# wiz16b8m4ct3_0_WIZ16B8M4CT3 register map
Vendor: Texas Instruments
Registers are 32-bit, read-write, reset 0x0 unless marked. A register's access mark holds for its fields unless they carry their own. Offsets are as the file gives them; [hi:lo] are bit positions; {n}, {i} and the like mark numbered series.

## wiz16b8m4ct3_0_WIZ16B8M4CT3 (part 11 of 12)
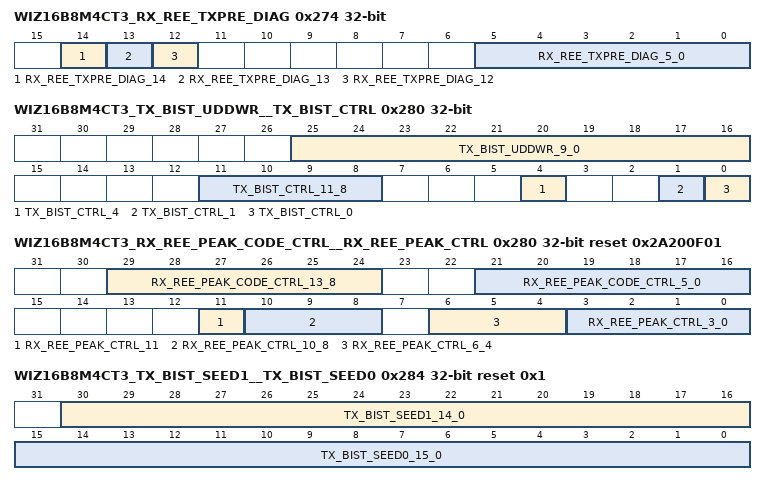
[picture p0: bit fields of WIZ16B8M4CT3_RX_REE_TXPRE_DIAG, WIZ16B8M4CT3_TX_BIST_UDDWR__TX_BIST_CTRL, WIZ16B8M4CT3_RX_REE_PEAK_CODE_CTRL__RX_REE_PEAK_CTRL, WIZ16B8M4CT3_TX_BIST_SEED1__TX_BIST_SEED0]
0x274 WIZ16B8M4CT3_RX_REE_TXPRE_DIAG access per field
  [14] RX_REE_TXPRE_DIAG_14 rw — Voter override neg : Writing a 1'b1 in this register bit will force the tap voter function to activate the voter neg signal for a single clock cycle. Note : This bit must be cleared after each time it is enabled, in order to perform follow on voter override functions with this bit. Note : It is not valid to activate both the voter override neg and voter override pos at the same time.
  [13] RX_REE_TXPRE_DIAG_13 rw — Voter override pos : Writing a 1'b1 in this register bit will force the tap voter function to activate the voter pos signal for a single clock cycle. Note : This bit must be cleared after each time it is enabled, in order to perform follow on voter override functions with this bit. Note : It is not valid to activate both the voter override neg and voter override pos at the same time.
  [12] RX_REE_TXPRE_DIAG_12 rw — Voter override enable : Setting this bit to a 1'b1 will allow only the voter override pos and voter override neg bits in this register to control the voter in the tap. Note : This function is intended to be for diagnostic and verification purposes only. Note : Both the voter override neg and voter override pos bits in this register must be set to 1'b0 when this bit is initially set to 1'b1 when enabling this function.
  [5:0] RX_REE_TXPRE_DIAG_5_0 ro — Current tap integrator accumulator: Current value of the tap integrator accumulator.
0x280 WIZ16B8M4CT3_TX_BIST_UDDWR__TX_BIST_CTRL access per field
  [25:16] TX_BIST_UDDWR_9_0 wo — Transmitter BIST user defined data: Writing a data word to this field will result in that data word being placed in the next available position in the transmitter BIST user defined data FIFO. Note, when in 20 bit mode, all 10 of these bits are used. When in 16 bit mode, only the least significant 8 bits are used. Note: The FIFO in this implementation is 18 words deep. It is up to the user to not write more than 18 words of data into this FIFO. Exceeding this amount of data will generate unpredictable results.
  [11:8] TX_BIST_CTRL_11_8 rw — Transmitter BIST mode: Controls which mode the BIST will operate in. The value of this field must match the corresponding field for the receive BIST controller. The following are the values used for this field, and what BIST mode they correspond to. 4'b0000 : User defined data FIFO 4'b0001 - 4'b0111 : Reserved 4'b1000 : PRBS7 : 7 bit LFSR 4'b1001 : PRBS15 : 15 bit LFSR 4'b1010 : PRBS23 : 23 bit LFSR 4'b1011 : PRBS31 : 31 bit LFSR 4'b1100 - 4'b1111 : Reserved
  [4] TX_BIST_CTRL_4 rw — Transmitter BIST force error: When this bit transitions from 1'b0 to 1'b1, the transmit BIST controller will force an error to be transmitted from the BIST logic, by inverting one of the parallel data bits.
  [1] TX_BIST_CTRL_1 wo — Transmitter BIST user defined data FIFO clear: Writing a 1'b1 to this bit will clear the transmitter BIST user defined data FIFO. Note : This bit is automatically cleared after it is written to. Note : This clear function simply resets the FIFO pointers. It does not clear the contents of the FIFO.
  [0] TX_BIST_CTRL_0 rw — Transmitter BIST enable: This bit enables the transmitter BIST function. Note : The remaining bits in this register must be stable when changing this bit. Therefore, it is best to enable and disable this function using a read / modify / write of this bit.
0x280 WIZ16B8M4CT3_RX_REE_PEAK_CODE_CTRL__RX_REE_PEAK_CTRL reset 0x2A200F01
  [29:24] RX_REE_PEAK_CODE_CTRL_13_8 — Peaking amp code maximum value: This is the maximum value that the peaking amp code will be allowed to increase to. Note: In this application the width of the integrator accumulator is 6, which is one larger that the number of bits required to generate a full 32 bit thermometer code. Therefore, as noted in the description of the REE gain integrator function, the thermometer code is generated using the most significant 5 bits of the integrator accumulator. As a result, the maximum value here needs to be 2X that of the maximum value of the thermometer encoded output.
  [21:16] RX_REE_PEAK_CODE_CTRL_5_0 — Peaking amp initial code: Initial value the peaking amp code is set to when training starts. Note: In this application the width of the integrator accumulator is 6, which is one larger that the number of bits required to generate a full 32 bit thermometer code. Therefore, as noted in the description of the REE gain integrator function, the thermometer code is generated using the most significant 5 bits of the integrator accumulator. As a result, the starting value here needs to be 2X that of the desired starting value of the thermometer encoded output.
  [11] RX_REE_PEAK_CTRL_11 — Peaking amp feedback path enable: Enables the peaking amp feedback path.
  [10:8] RX_REE_PEAK_CTRL_10_8 — Peaking amp feedback scaler value: Specifies the amount to scale the peaking amp feedback by. The following are the valid settings for this signal: 3'b110 : /4 3'b111 : /2 3'b000 : x1 3'b001 : x2 3'b010 : x4
  [6:4] RX_REE_PEAK_CTRL_6_4 — Peaking amp integrator accumulator scaler value: Specifies the amount to scale the input to the peaking amp integrator accumulator by. The following are the valid settings for this field: 3'b000: x1 3'b001: x2 3'b010: x4 3'b011: x8 3'b100: x16 3'b101 - 3'b111: Reserved
  [3:0] RX_REE_PEAK_CTRL_3_0 — Peaking amp sigma delta accumulator scaler value: Specifies the amount to scale the input to the peaking amp sigma delta accumulator by. The following are the valid settings for this field: 4'b0000: x1 4'b0001: x2 4'b0010: x4 4'b0011: x8 4'b0100: x16 4'b0101: x 32 4'b0110: x 64 4'b0111: x128 4'b1000: x256 4'b1001: x512 4'b1010: x1024 4'b1011: x2048 4'b1100: x 4096 4'b1101 x 8192 4'b1110 x 16384 4'b1111 x 32768
0x284 WIZ16B8M4CT3_TX_BIST_SEED1__TX_BIST_SEED0 reset 0x1
  [30:16] TX_BIST_SEED1_14_0 — Transmitter BIST PRBS seed (30:16): When the BIST is in PRBS mode, this field provides a seed for the PRBS, such that different lanes can have different BIST patterns. Note: This field contains the most significant 15 bits of the full 31 bit seed value. Note: When combined, this register and the Transmit BIST PRBS seed 0 register on page 223 must never be all 0s.
  [15:0] TX_BIST_SEED0_15_0 — Transmitter BIST PRBS seed (15:0): When the BIST is in PRBS mode, this field provides a seed for the PRBS, such that different lanes can have different BIST patterns. Note: This field contains the least significant 16 bits of the full 31 bit seed value. Note: When combined, this register and the Transmit BIST PRBS seed 1 register on page 224 must never be all 0s.
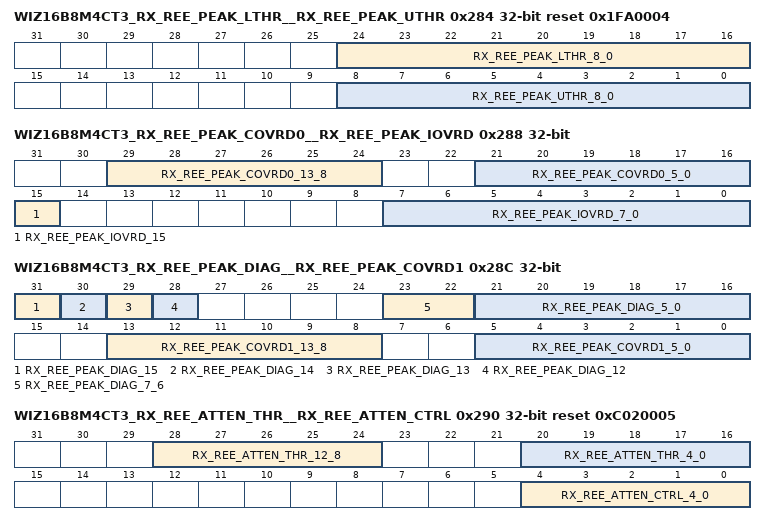
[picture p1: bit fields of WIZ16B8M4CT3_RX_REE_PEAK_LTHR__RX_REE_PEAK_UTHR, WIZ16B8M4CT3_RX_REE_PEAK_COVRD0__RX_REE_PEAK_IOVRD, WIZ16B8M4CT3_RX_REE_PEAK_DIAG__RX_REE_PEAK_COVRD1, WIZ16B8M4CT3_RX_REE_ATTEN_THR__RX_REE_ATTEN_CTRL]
0x284 WIZ16B8M4CT3_RX_REE_PEAK_LTHR__RX_REE_PEAK_UTHR reset 0x1FA0004
  [24:16] RX_REE_PEAK_LTHR_8_0 — Peaking amp algorithm lower threshold: This is the lower threshold value used in the peaking amp algorithm.
  [8:0] RX_REE_PEAK_UTHR_8_0 — Peaking amp algorithm upper threshold: This is the upper threshold value used in the peaking amp algorithm.
0x288 WIZ16B8M4CT3_RX_REE_PEAK_COVRD0__RX_REE_PEAK_IOVRD
  [29:24] RX_REE_PEAK_COVRD0_13_8 — Peaking amp code override value mode 1: Value that will override the peaking amp code when in standard mode 1 when the peaking amp code override enable bit in the REE peaking amp diagnostics register (!) on page 276 is active. The value of this override field will ultimately drive the thermometer encoded value on the rxda_dfe_peaking_amp_gain signal driven to the analog.
  [21:16] RX_REE_PEAK_COVRD0_5_0 — Peaking amp code override value mode 0: Value that will override the peaking amp code when in standard mode 0 when the peaking amp code override enable bit in the REE peaking amp diagnostics register (!) on page 276 is active. The value of this override field will ultimately drive the thermometer encoded value on the rxda_dfe_peaking_amp_gain signal driven to the analog.
  [15] RX_REE_PEAK_IOVRD_15 — Peaking amp tap accumulator input override enable: Setting this bit to a 1'b1 will allow the tap accumulator input in the peaking amp gain algorithm to be overridden by the peaking amp tap accumulator input override field in this register.
  [7:0] RX_REE_PEAK_IOVRD_7_0 — Peaking amp tap accumulator input override : Value that will override the tap accumulator input in the peaking amp gain algorithm, when the Peaking amp tap accumulator input override enable bit is active.
0x28C WIZ16B8M4CT3_RX_REE_PEAK_DIAG__RX_REE_PEAK_COVRD1 access per field
  [31] RX_REE_PEAK_DIAG_15 rw — Peaking amp code override enable: Setting this bit to a 1'b1 will allow the peaking amp code to be overridden by the peaking amp code override value fields in the REE peaking amp code override 0 register (!) on page 274 and REE peaking amp code override 1 register (!) on page 275.
  [30] RX_REE_PEAK_DIAG_14 rw — Voter override neg : Writing a 1'b1 in this register bit will force the peaking amp voter function to activate the voter neg signal for a single clock cycle. Note : This bit must be cleared after each time it is enabled, in order to perform follow on voter override functions with this bit. Note : It is not valid to activate both the voter override neg and voter override pos at the same time.
  [29] RX_REE_PEAK_DIAG_13 rw — Voter override pos : Writing a 1'b1 in this register bit will force the peaking amp voter function to activate the voter pos signal for a single clock cycle. Note : This bit must be cleared after each time it is enabled, in order to perform follow on voter override functions with this bit. Note : It is not valid to activate both the voter override neg and voter override pos at the same time.
  [28] RX_REE_PEAK_DIAG_12 rw — Voter override enable : Setting this bit to a 1'b1 will allow only the voter override pos and voter override neg bits in this register to control the voter in the peaking amp. Note : This function is intended to be for diagnostic and verification purposes only. Note : Both the voter override neg and voter override pos bits in this register must be set to 1'b0 when this bit is initially set to 1'b1 when enabling this function.
  [23:22] RX_REE_PEAK_DIAG_7_6 ro — Reserved Note : n = CODE_WIDTH.
  [21:16] RX_REE_PEAK_DIAG_5_0 ro — Current peaking amp integrator accumulator: Current value of the tap integrator accumulator, without the unused sign bit. Note: The reset value for this field is with the transceiver data path power island switched off. In cases where this power island is switched on, the reset value be 6'b100000
  [13:8] RX_REE_PEAK_COVRD1_13_8 rw — Peaking amp code override value mode 3: Value that will override the peaking amp code when in standard mode 3 when the peaking amp code override enable bit in the REE peaking amp diagnostics register (!) on page 276 is active. The value of this override field will ultimately drive the thermometer encoded value on the rxda_dfe_peaking_amp_gain signal driven to the analog.
  [5:0] RX_REE_PEAK_COVRD1_5_0 rw — Peaking amp code override value mode 2: Value that will override the peaking amp code when in standard mode 2 when the peaking amp code override enable bit in the REE peaking amp diagnostics register (!) on page 276 is active. The value of this override field will ultimately drive the thermometer encoded value on the rxda_dfe_peaking_amp_gain signal driven to the analog.
0x290 WIZ16B8M4CT3_RX_REE_ATTEN_THR__RX_REE_ATTEN_CTRL reset 0xC020005
  [28:24] RX_REE_ATTEN_THR_12_8 — Attenuation high threshold value: High threshold value to compare against the VGA gain accumulator value. Note: The value on this field is not a twos complement value (There is no sign bit and it is always a positive number).
  [20:16] RX_REE_ATTEN_THR_4_0 — Attenuation low threshold value: Low threshold value to compare against the VGA gain accumulator value. Note: The value on this field is not a twos complement value (There is no sign bit and it is always a positive number).
  [4:0] RX_REE_ATTEN_CTRL_4_0 — Receiver DFE attenuation maximum value: The maximum value the rxda_dfe_attenuation_bin will increase to. Note: The value on this field is not a twos complement value (There is no sign bit and it is always a positive number).
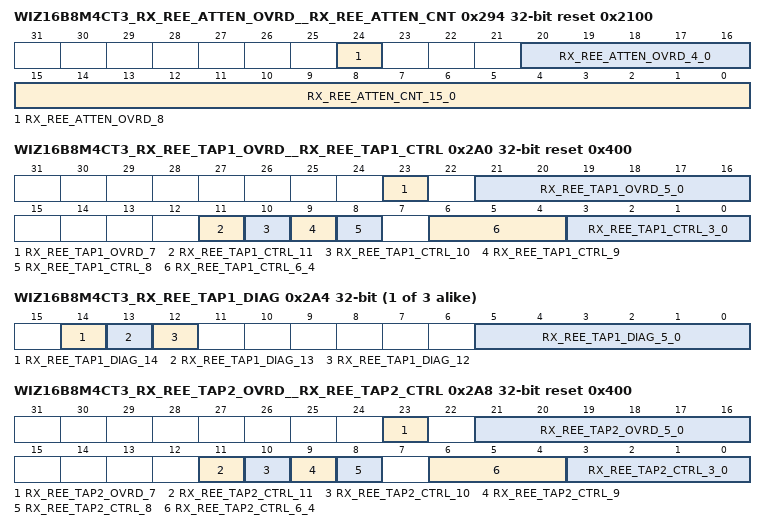
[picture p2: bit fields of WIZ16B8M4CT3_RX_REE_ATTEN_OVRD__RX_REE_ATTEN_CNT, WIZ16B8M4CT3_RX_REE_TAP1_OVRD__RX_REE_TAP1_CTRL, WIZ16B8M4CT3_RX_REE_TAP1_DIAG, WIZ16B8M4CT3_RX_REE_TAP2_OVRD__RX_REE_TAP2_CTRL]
0x294 WIZ16B8M4CT3_RX_REE_ATTEN_OVRD__RX_REE_ATTEN_CNT reset 0x2100
  [24] RX_REE_ATTEN_OVRD_8 — Attenuation override enable: Setting this bit to a 1'b1 will allow the rxda_dfe_attenuation_bin signal to be overridden by the attenuation override value signal in this register.
  [20:16] RX_REE_ATTEN_OVRD_4_0 — Attenuation override value: When enabled by the attenuation override enable bit in this register, this value will override the current attenuation value on the rxda_dfe_attenuation_bin output pin, and also force a corresponding change on the rxda_dfe_attenuation_therm pin. The following specifies the values that can be written to this register. 6'b000000: Min 6'b000001 6'b000011 6'b000111 6'b001111 6'b011111 6'b111111: Max
  [15:0] RX_REE_ATTEN_CNT_15_0 — Attenuation counter max: Value used to specify the maximum number of consecutive words above or below the specified thresholds which will result in triggering an increase or decrease in the rxda_dfe_attenuation_bin signal.
0x298 WIZ16B8M4CT3_RX_REE_ATTEN_DIAG ro
  [4:0] RX_REE_ATTEN_DIAG_4_0 — Current attenuation value: Current value of the attenuation.
0x2A0 WIZ16B8M4CT3_RX_REE_TAP1_OVRD__RX_REE_TAP1_CTRL reset 0x400
  [23] RX_REE_TAP1_OVRD_7 — Tap override enable: Setting this bit to a 1'b1 will enable the tap override field in this register to override the tap integrator accumulator functions.
  [21:16] RX_REE_TAP1_OVRD_5_0 — Tap override value: When the tap override enable bit in this register is active, the value in this field will override the integrator accumulator value, as well as the input to the binary to thermometer encoder.
  [11] RX_REE_TAP1_CTRL_11 — Tap coefficient combinational logic zero crossing enable: 1'b0: Zero crossing combinational logic input not enabled. 1'b1: Zero crossing combinational logic input enabled.
  [10] RX_REE_TAP1_CTRL_10 — Tap coefficient combinational logic non zero crossing enable: 1'b0: non zero crossing combinational logic input not enabled. 1'b1: non zero crossing combinational logic input enabled.
  [9] RX_REE_TAP1_CTRL_9 — Tap coefficient combinational logic bit 0 only enable: 1'b0: All enabled combinational logic input modules will be used. 1'b1: Only the enabled combinational logic input modules associated with bit 0 will be used.
  [8] RX_REE_TAP1_CTRL_8 — Receiver DFE tap coefficient disable: This bit disables the rxda_dfe_tap_coef output signal. 1'b0 : rxda_dfe_tap_coef output enabled. 1'b1 : rxda_dfe_tap_coef output disabled (all 0s).
  [6:4] RX_REE_TAP1_CTRL_6_4 — Tap integrator accumulator scaler value: Specifies the amount to scale the input to the tap integrator accumulator by. The following are the valid settings for this field: 3'b000: x1 3'b001 - 3'b111: Reserved
  [3:0] RX_REE_TAP1_CTRL_3_0 — Tap sigma delta accumulator scaler value: Specifies the amount to scale the input to the tap sigma delta accumulator by. The following are the valid settings for this field: 4'b0000: x1 4'b0001: x2 4'b0010: x4 4'b0011: x8 4'b0100: x16 4'b0101: x 32 4'b0110: x 64 4'b0111: x128 4'b1000: x256 4'b1001: x512 4'b1010: x1024 4'b1011: x2048 4'b1100: x 4096 4'b1101 x 8192 4'b1110 x 16384 4'b1111 x 32768
{0x29C+8i} WIZ16B8M4CT3_RX_REE_TAP{i}_DIAG access per field (i=1..3)
  [14] RX_REE_TAP{i}_DIAG_14 rw — Voter override neg : Writing a 1'b1 in this register bit will force the tap voter function to activate the voter neg signal for a single clock cycle. Note : This bit must be cleared after each time it is enabled, in order to perform follow on voter override functions with this bit. Note : It is not valid to activate both the voter override neg and voter override pos at the same time.
  [13] RX_REE_TAP{i}_DIAG_13 rw — Voter override pos : Writing a 1'b1 in this register bit will force the tap voter function to activate the voter pos signal for a single clock cycle. Note : This bit must be cleared after each time it is enabled, in order to perform follow on voter override functions with this bit. Note : It is not valid to activate both the voter override neg and voter override pos at the same time.
  [12] RX_REE_TAP{i}_DIAG_12 rw — Voter override enable : Setting this bit to a 1'b1 will allow only the voter override pos and voter override neg bits in this register to control the voter in the tap. Note : This function is intended to be for diagnostic and verification purposes only. Note : Both the voter override neg and voter override pos bits in this register must be set to 1'b0 when this bit is initially set to 1'b1 when enabling this function.
  [5:0] RX_REE_TAP{i}_DIAG_5_0 ro — Current tap integrator accumulator: Current value of the tap integrator accumulator.
0x2A8 WIZ16B8M4CT3_RX_REE_TAP2_OVRD__RX_REE_TAP2_CTRL reset 0x400
  [23] RX_REE_TAP2_OVRD_7 — Tap override enable: Setting this bit to a 1'b1 will enable the tap override field in this register to override the tap integrator accumulator functions.
  [21:16] RX_REE_TAP2_OVRD_5_0 — Tap override value: When the tap override enable bit in this register is active, the value in this field will override the integrator accumulator value, as well as the input to the binary to thermometer encoder.
  [11] RX_REE_TAP2_CTRL_11 — Tap coefficient combinational logic zero crossing enable: 1'b0: Zero crossing combinational logic input not enabled. 1'b1: Zero crossing combinational logic input enabled. (This mode is currently not supported)
  [10] RX_REE_TAP2_CTRL_10 — Tap coefficient combinational logic non zero crossing enable: 1'b0: non zero crossing combinational logic input not enabled. 1'b1: non zero crossing combinational logic input enabled.
  [9] RX_REE_TAP2_CTRL_9 — Tap coefficient combinational logic bit 0 only enable: 1'b0: All enabled combinational logic input modules will be used. 1'b1: Only the enabled combinational logic input modules associated with bit 0 will be used.
  [8] RX_REE_TAP2_CTRL_8 — Receiver DFE tap coefficient disable: This bit disables the rxda_dfe_tap_coef output signal. 1'b0 : rxda_dfe_tap_coef output enabled. 1'b1 : rxda_dfe_tap_coef output disabled (all 0s).
  [6:4] RX_REE_TAP2_CTRL_6_4 — Tap integrator accumulator scaler value: Specifies the amount to scale the input to the tap integrator accumulator by. The following are the valid settings for this field: 3'b000: x1 3'b001 - 3'b111: Reserved
  [3:0] RX_REE_TAP2_CTRL_3_0 — Tap sigma delta accumulator scaler value: Specifies the amount to scale the input to the tap sigma delta accumulator by. The following are the valid settings for this field: 4'b0000: x1 4'b0001: x2 4'b0010: x4 4'b0011: x8 4'b0100: x16 4'b0101: x 32 4'b0110: x 64 4'b0111: x128 4'b1000: x256 4'b1001: x512 4'b1010: x1024 4'b1011: x2048 4'b1100: x 4096 4'b1101 x 8192 4'b1110 x 16384 4'b1111 x 32768
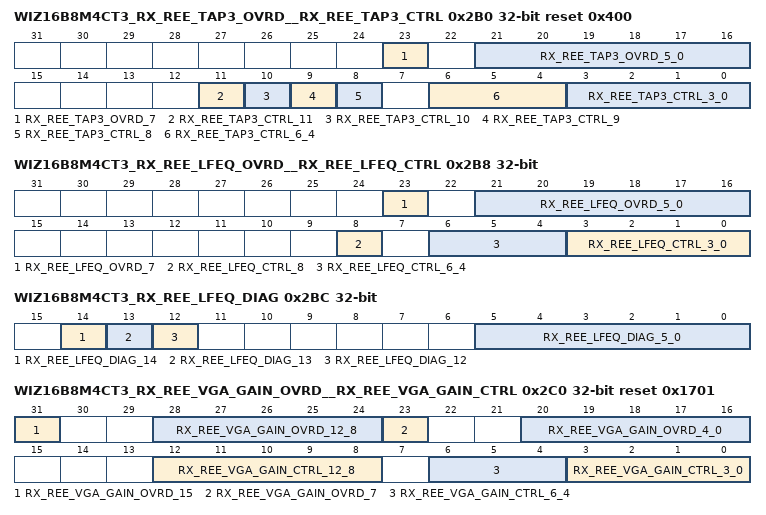
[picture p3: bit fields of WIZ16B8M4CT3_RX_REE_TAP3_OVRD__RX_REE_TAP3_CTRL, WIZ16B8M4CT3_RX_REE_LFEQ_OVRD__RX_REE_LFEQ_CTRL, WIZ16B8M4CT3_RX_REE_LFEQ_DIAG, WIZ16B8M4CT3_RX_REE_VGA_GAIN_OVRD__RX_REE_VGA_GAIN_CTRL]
0x2B0 WIZ16B8M4CT3_RX_REE_TAP3_OVRD__RX_REE_TAP3_CTRL reset 0x400
  [23] RX_REE_TAP3_OVRD_7 — Tap override enable: Setting this bit to a 1'b1 will enable the tap override field in this register to override the tap integrator accumulator functions.
  [21:16] RX_REE_TAP3_OVRD_5_0 — Tap override value: When the tap override enable bit in this register is active, the value in this field will override the integrator accumulator value, as well as the input to the binary to thermometer encoder.
  [11] RX_REE_TAP3_CTRL_11 — Tap coefficient combinational logic zero crossing enable: 1'b0: Zero crossing combinational logic input not enabled. 1'b1: Zero crossing combinational logic input enabled. (This mode is currently not supported)
  [10] RX_REE_TAP3_CTRL_10 — Tap coefficient combinational logic non zero crossing enable: 1'b0: non zero crossing combinational logic input not enabled. 1'b1: non zero crossing combinational logic input enabled.
  [9] RX_REE_TAP3_CTRL_9 — Tap coefficient combinational logic bit 0 only enable: 1'b0: All enabled combinational logic input modules will be used. 1'b1: Only the enabled combinational logic input modules associated with bit 0 will be used.
  [8] RX_REE_TAP3_CTRL_8 — Receiver DFE tap coefficient disable: This bit disables the rxda_dfe_tap_coef output signal. 1'b0 : rxda_dfe_tap_coef output enabled. 1'b1 : rxda_dfe_tap_coef output disabled (all 0s).
  [6:4] RX_REE_TAP3_CTRL_6_4 — Tap integrator accumulator scaler value: Specifies the amount to scale the input to the tap integrator accumulator by. The following are the valid settings for this field: 3'b000: x1 3'b001 - 3'b111: Reserved
  [3:0] RX_REE_TAP3_CTRL_3_0 — Tap sigma delta accumulator scaler value: Specifies the amount to scale the input to the tap sigma delta accumulator by. The following are the valid settings for this field: 4'b0000: x1 4'b0001: x2 4'b0010: x4 4'b0011: x8 4'b0100: x16 4'b0101: x 32 4'b0110: x 64 4'b0111: x128 4'b1000: x256 4'b1001: x512 4'b1010: x1024 4'b1011: x2048 4'b1100: x 4096 4'b1101 x 8192 4'b1110 x 16384 4'b1111 x 32768
0x2B8 WIZ16B8M4CT3_RX_REE_LFEQ_OVRD__RX_REE_LFEQ_CTRL
  [23] RX_REE_LFEQ_OVRD_7 — Override enable: Setting this bit to a 1'b1 will enable the override field in this register to override the integrator accumulator functions.
  [21:16] RX_REE_LFEQ_OVRD_5_0 — Override value: When the override enable bit in this register is active, the value in this field will override the integrator accumulator value, as well as the input to the binary to thermometer encoder.
  [8] RX_REE_LFEQ_CTRL_8 — Receiver DFE coefficient disable: This bit disables the rxda_dfe_coef output signal. 1'b0 : rxda_dfe_coef output enabled. 1'b1 : rxda_dfe_coef output disabled (all 0s).
  [6:4] RX_REE_LFEQ_CTRL_6_4 — Integrator accumulator scaler value: Specifies the amount to scale the input to the integrator accumulator by. The following are the valid settings for this field: 3'b000: x1 3'b001: x2 3'b010: x4 3'b011: x8 3'b100: x16 3'b101 - 3'b111: Reserved
  [3:0] RX_REE_LFEQ_CTRL_3_0 — Sigma delta accumulator scaler value: Specifies the amount to scale the input to the sigma delta accumulator by. The following are the valid settings for this field: 4'b0000: x1 4'b0001: x2 4'b0010: x4 4'b0011: x8 4'b0100: x16 4'b0101: x 32 4'b0110: x 64 4'b0111: x128 4'b1000: x256 4'b1001: x512 4'b1010: x1024 4'b1011: x2048 4'b1100: x 4096 4'b1101 x 8192 4'b1110 x 16384 4'b1111 x 32768
0x2BC WIZ16B8M4CT3_RX_REE_LFEQ_DIAG access per field
  [14] RX_REE_LFEQ_DIAG_14 rw — Voter override neg : Writing a 1'b1 in this register bit will force the voter function to activate the voter neg signal for a single clock cycle. Note : This bit must be cleared after each time it is enabled, in order to perform follow on voter override functions with this bit. Note : It is not valid to activate both the voter override neg and voter override pos at the same time.
  [13] RX_REE_LFEQ_DIAG_13 rw — Voter override pos : Writing a 1'b1 in this register bit will force the voter function to activate the voter pos signal for a single cycle. Note : This bit must be cleared after each time it is enabled, in order to perform follow on voter override functions with this bit. Note : It is not valid to activate both the voter override neg and voter override pos at the same time.
  [12] RX_REE_LFEQ_DIAG_12 rw — Voter override enable : Setting this bit to a 1'b1 will allow only the voter override pos and voter override neg bits in this register to control the voter. Note : This function is intended to be for diagnostic and verification purposes only. Note : Both the voter override neg and voter override pos bits in this register must be set to 1'b0 when this bit is initially set to 1'b1 when enabling this function.
  [5:0] RX_REE_LFEQ_DIAG_5_0 ro — Current integrator accumulator: Current value of the integrator accumulator.
0x2C0 WIZ16B8M4CT3_RX_REE_VGA_GAIN_OVRD__RX_REE_VGA_GAIN_CTRL reset 0x1701
  [31] RX_REE_VGA_GAIN_OVRD_15 — VGA gain target adjust override enable: Setting this bit to a 1'b1 will enable the VGA gain target adjust override field in this register to override the VGA gain target adjust accumulator functions.
  [28:24] RX_REE_VGA_GAIN_OVRD_12_8 — VGA gain target adjust override value: When the VGA gain target adjust override enable bit in this register is active, the value in this field will override the accumulator value used to drive the vga_gain_tgt_adj signal.
  [23] RX_REE_VGA_GAIN_OVRD_7 — VGA gain override enable: Setting this bit to a 1'b1 will enable the VGA gain override field in this register to override the VGA gain integrator accumulator functions.
  [20:16] RX_REE_VGA_GAIN_OVRD_4_0 — VGA gain override value: When the VGA gain override enable bit in this register is active, the value in this field will override the integrator accumulator value, as well as the input to the binary to thermometer encoder.
  [12:8] RX_REE_VGA_GAIN_CTRL_12_8 — VGA gain max: Specifies the maximum value of the VGA gain integrator accumulator, and therefore also the maximum number of bits in the rxda_dfe_vga_gain thermometer code that will be set.
  [6:4] RX_REE_VGA_GAIN_CTRL_6_4 — VGA gain integrator accumulator scaler value: Specifies the amount to scale the input to the VGA gain integrator accumulator by. The following are the valid settings for this field: 3'b000: x1 3'b001: x2 3'b010: x4 3'b011: x8 3'b100: x16 3'b101 - 3'b111: Reserved
  [3:0] RX_REE_VGA_GAIN_CTRL_3_0 — VGA gain sigma delta accumulator scaler value: Specifies the amount to scale the input to the VGA gain sigma delta accumulator by. The following are the valid settings for this field: 4'b0000: x1 4'b0001: x2 4'b0010: x4 4'b0011: x8 4'b0100: x16 4'b0101: x 32 4'b0110: x 64 4'b0111: x128 4'b1000: x256 4'b1001: x512 4'b1010: x1024 4'b1011: x2048 4'b1100: x 4096 4'b1101 x 8192 4'b1110 x 16384 4'b1111 x 32768
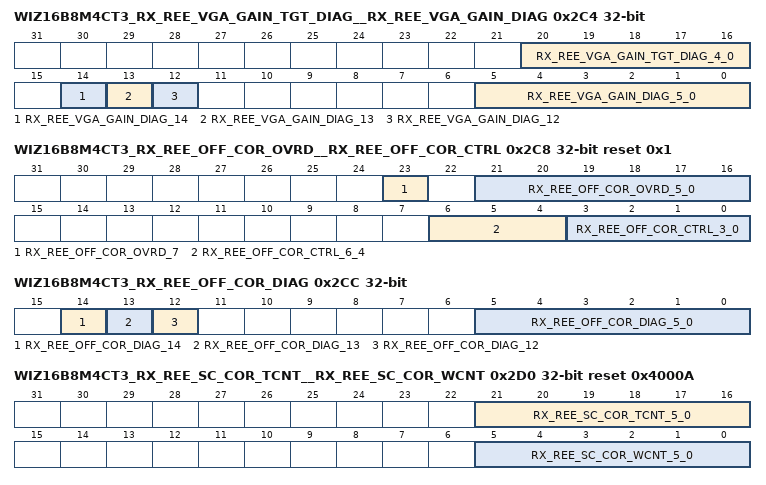
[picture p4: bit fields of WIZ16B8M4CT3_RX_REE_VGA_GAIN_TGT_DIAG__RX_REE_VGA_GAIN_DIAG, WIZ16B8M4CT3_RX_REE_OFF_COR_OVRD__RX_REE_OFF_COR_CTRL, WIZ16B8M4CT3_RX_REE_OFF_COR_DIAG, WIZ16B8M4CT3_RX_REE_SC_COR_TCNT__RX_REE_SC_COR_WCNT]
0x2C4 WIZ16B8M4CT3_RX_REE_VGA_GAIN_TGT_DIAG__RX_REE_VGA_GAIN_DIAG access per field
  [20:16] RX_REE_VGA_GAIN_TGT_DIAG_4_0 ro — Current VGA gain integrator accumulator: Current value of the VGA gain integrator accumulator.
  [14] RX_REE_VGA_GAIN_DIAG_14 rw — Voter override neg : Writing a 1'b1 in this register bit will force the VGA gain voter function to activate the voter neg signal for a single clock cycle. Note : This bit must be cleared after each time it is enabled, in order to perform follow on voter override functions with this bit. Note : It is not valid to activate both the voter override neg and voter override pos at the same time.
  [13] RX_REE_VGA_GAIN_DIAG_13 rw — Voter override pos : Writing a 1'b1 in this register bit will force the VGA gain voter function to activate the voter pos signal for a single clock cycle. Note : This bit must be cleared after each time it is enabled, in order to perform follow on voter override functions with this bit. Note : It is not valid to activate both the voter override neg and voter override pos at the same time.
  [12] RX_REE_VGA_GAIN_DIAG_12 rw — Voter override enable : Setting this bit to a 1'b1 will allow only the voter override pos and voter override neg bits in this register to control the voter in the VGA gain. Note : This function is intended to be for diagnostic and verification purposes only. Note : Both the voter override neg and voter override pos bits in this register must be set to 1'b0 when this bit is initially set to 1'b1 when enabling this function.
  [5:0] RX_REE_VGA_GAIN_DIAG_5_0 ro — Current VGA gain integrator accumulator: Current value of the VGA gain integrator accumulator. Note: The reset value for this field is with the transceiver data path power island switched off. In cases where this power island is switched on, the reset value be 6'b001010
0x2C8 WIZ16B8M4CT3_RX_REE_OFF_COR_OVRD__RX_REE_OFF_COR_CTRL reset 0x1
  [23] RX_REE_OFF_COR_OVRD_7 — Offset correction override enable: Setting this bit to a 1'b1 will enable the offset correction override field in this register to override the offset correction integrator accumulator functions.
  [21:16] RX_REE_OFF_COR_OVRD_5_0 — Offset correction override value: When the offset correction override enable bit in this register is active, the value in this field will override the integrator accumulator value, as well as the input to the binary to thermometer encoder.
  [6:4] RX_REE_OFF_COR_CTRL_6_4 — Offset correction integrator accumulator scaler value: Specifies the amount to scale the input to the offset correction integrator accumulator by. The following are the valid settings for this field: 3'b000: x1 3'b001: x2 3'b010: x4 3'b011: x8 3'b100: x16 3'b101 - 3'b111: Reserved
  [3:0] RX_REE_OFF_COR_CTRL_3_0 — Offset correction sigma delta accumulator scaler value: Specifies the amount to scale the input to the offset correction sigma delta accumulator by. The following are the valid settings for this field: 4'b0000: x1 4'b0001: x2 4'b0010: x4 4'b0011: x8 4'b0100: x16 4'b0101: x 32 4'b0110: x 64 4'b0111: x128 4'b1000: x256 4'b1001: x512 4'b1010: x1024 4'b1011: x2048 4'b1100: x 4096 4'b1101 x 8192 4'b1110 x 16384 4'b1111 x 32768
0x2CC WIZ16B8M4CT3_RX_REE_OFF_COR_DIAG access per field
  [14] RX_REE_OFF_COR_DIAG_14 rw — Voter override neg : Writing a 1'b1 in this register bit will force the offset correction voter function to activate the voter neg signal for a single clock cycle. Note : This bit must be cleared after each time it is enabled, in order to perform follow on voter override functions with this bit. Note : It is not valid to activate both the voter override neg and voter override pos at the same time.
  [13] RX_REE_OFF_COR_DIAG_13 rw — Voter override pos : Writing a 1'b1 in this register bit will force the offset correction voter function to activate the voter pos signal for a single clock cycle. Note : This bit must be cleared after each time it is enabled, in order to perform follow on voter override functions with this bit. Note : It is not valid to activate both the voter override neg and voter override pos at the same time.
  [12] RX_REE_OFF_COR_DIAG_12 rw — Voter override enable : Setting this bit to a 1'b1 will allow only the voter override pos and voter override neg bits in this register to control the voter in the offset correction. Note : This function is intended to be for diagnostic and verification purposes only. Note : Both the voter override neg and voter override pos bits in this register must be set to 1'b0 when this bit is initially set to 1'b1 when enabling this function.
  [5:0] RX_REE_OFF_COR_DIAG_5_0 ro — Current offset correction integrator accumulator: Current value of the offset correction integrator accumulator.
0x2D0 WIZ16B8M4CT3_RX_REE_SC_COR_TCNT__RX_REE_SC_COR_WCNT reset 0x4000A
  [21:16] RX_REE_SC_COR_TCNT_5_0 — Threshold counter start value : Value used for the starting value when counting the number of bits that are below the error threshold.
  [5:0] RX_REE_SC_COR_WCNT_5_0 — Valid word counter start value : Value used for the starting value when counting the number of valid words.
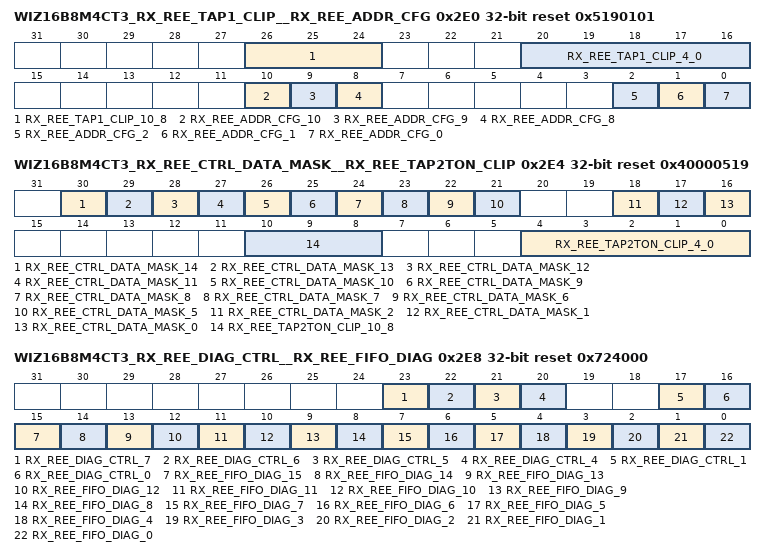
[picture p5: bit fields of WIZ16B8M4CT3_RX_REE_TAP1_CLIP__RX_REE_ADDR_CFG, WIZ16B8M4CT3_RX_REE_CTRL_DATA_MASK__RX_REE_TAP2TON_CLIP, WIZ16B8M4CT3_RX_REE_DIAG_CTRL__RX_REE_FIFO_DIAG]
0x2E0 WIZ16B8M4CT3_RX_REE_TAP1_CLIP__RX_REE_ADDR_CFG reset 0x5190101
  [26:24] RX_REE_TAP1_CLIP_10_8 — VGA target gain adjust multiplier: Controls how much to multiply the VGA target gain adjust by, when calculating the tap threshold. The following are valid values, and the corresponding multiplier values. 3'b000 : x 0.00 3'b001 : x 0.25 3'b010 : x 0.50 3'b011 : x 0.75 3'b100 : x 1.00 3'b101 : x 1.25 3'b110 : x 1.50 3'b111 : x 1.75 Note : By setting this field to 3'b000, the threshold value of the tap can be directly controlled by the threshold adjust field in this register. Note : The VGA gain adjust signal is always a negative number.
  [20:16] RX_REE_TAP1_CLIP_4_0 — Threshold adjust: Controls how much the threshold can be adjusted by, after multiplying the VGA target gain adjust multiplier with the VGA target gain adjust. Note: This field is a positive number (not twos complement). Note : This field must not be set to a value of 0. Note : The combination of the multiplier and threshold fields in this register controls the positive and negative thresholds for the taps, according to the following equation. Note: The logic associated with this limits the range of the magnitude to 0 to 31, before creating the positive and negative thresholds. +/- ((VGA target gain adjust * VGA target gain adjust multiplier) + Threshold adjust)
  [10] RX_REE_ADDR_CFG_10 — TX post cursor tap 3 adder enable: Setting this bit to 1'b1, enables the results of tap 3 to be added to the TX post cursor controller input.
  [9] RX_REE_ADDR_CFG_9 — TX post cursor tap 2 adder enable: Setting this bit to 1'b1, enables the results of tap 2 to be added to the TX post cursor controller input.
  [8] RX_REE_ADDR_CFG_8 — TX post cursor tap 1 adder enable: Setting this bit to 1'b1, enables the results of tap 1 to be added to the TX post cursor controller input.
  [2] RX_REE_ADDR_CFG_2 — RX peaking tap 3 adder enable: Setting this bit to 1'b1, enables the results of tap 3 to be added to the RX peaking amp gain input.
  [1] RX_REE_ADDR_CFG_1 — RX peaking tap 2 adder enable: Setting this bit to 1'b1, enables the results of tap 2 to be added to the RX peaking amp gain input.
  [0] RX_REE_ADDR_CFG_0 — RX peaking tap 1 adder enable: Setting this bit to 1'b1, enables the results of tap 1 to be added to the RX peaking amp gain input.
0x2E4 WIZ16B8M4CT3_RX_REE_CTRL_DATA_MASK__RX_REE_TAP2TON_CLIP access per field reset 0x40000519
  [30] RX_REE_CTRL_DATA_MASK_14 ro — Ignore 1010 controller Note: This is read only. This should never be disabled.
  [29] RX_REE_CTRL_DATA_MASK_13 rw — TX equalization evaluator: When set to 1'b0, this REE component will be turned off when control data is being received, when either the rx_eq_training_data_valid signal going inactive, or a 1010 pattern is detected on the data signals by the REE.
  [28] RX_REE_CTRL_DATA_MASK_12 rw — TX post cursor control: When set to 1'b0, this REE component will be turned off when control data is being received, when either the rx_eq_training_data_valid signal going inactive, or a 1010 pattern is detected on the data signals by the REE.
  [27] RX_REE_CTRL_DATA_MASK_11 rw — TX pre cursor control: When set to 1'b0, this REE component will be turned off when control data is being received, when either the rx_eq_training_data_valid signal going inactive, or a 1010 pattern is detected on the data signals by the REE.
  [26] RX_REE_CTRL_DATA_MASK_10 rw — Short channel correction: When set to 1'b0, this REE component will be turned off when control data is being received, when either the rx_eq_training_data_valid signal going inactive, or a 1010 pattern is detected on the data signals by the REE.
  [25] RX_REE_CTRL_DATA_MASK_9 rw — RX attenuation: When set to 1'b0, this REE component will be turned off when control data is being received, when either the rx_eq_training_data_valid signal going inactive, or a 1010 pattern is detected on the data signals by the REE.
  [24] RX_REE_CTRL_DATA_MASK_8 rw — RX VGA gain: When set to 1'b0, this REE component will be turned off when control data is being received, when either the rx_eq_training_data_valid signal going inactive, or a 1010 pattern is detected on the data signals by the REE.
  [23] RX_REE_CTRL_DATA_MASK_7 rw — RX offset correction coefficient: When set to 1'b0, this REE component will be turned off when control data is being received, when either the rx_eq_training_data_valid signal going inactive, or a 1010 pattern is detected on the data signals by the REE.
  [22] RX_REE_CTRL_DATA_MASK_6 rw — RX peaking amp gain: When set to 1'b0, this REE component will be turned off when control data is being received, when either the rx_eq_training_data_valid signal going inactive, or a 1010 pattern is detected on the data signals by the REE.
  [21] RX_REE_CTRL_DATA_MASK_5 rw — RX low frequency equalizer adaptive control: When set to 1'b0, this REE component will be turned off when control data is being received, when either the rx_eq_training_data_valid signal going inactive, or a 1010 pattern is detected on the data signals by the REE.
  [18] RX_REE_CTRL_DATA_MASK_2 rw — RX tap 3: When set to 1'b0, this REE component will be turned off when control data is being received, when either the rx_eq_training_data_valid signal going inactive, or a 1010 pattern is detected on the data signals by the REE.
  [17] RX_REE_CTRL_DATA_MASK_1 rw — RX tap 2: When set to 1'b0, this REE component will be turned off when control data is being received, when either the rx_eq_training_data_valid signal going inactive, or a 1010 pattern is detected on the data signals by the REE.
  [16] RX_REE_CTRL_DATA_MASK_0 rw — RX tap 1: When set to 1'b0, this REE component will be turned off when control data is being received, when either the rx_eq_training_data_valid signal going inactive, or a 1010 pattern is detected on the data signals by the REE.
  [10:8] RX_REE_TAP2TON_CLIP_10_8 rw — VGA target gain adjust multiplier: Controls how much to multiply the VGA target gain adjust by, when calculating the tap threshold. The following are valid values, and the corresponding multiplier values. 3'b000 : x 0.00 3'b001 : x 0.25 3'b010 : x 0.50 3'b011 : x 0.75 3'b100 : x 1.00 3'b101 : x 1.25 3'b110 : x 1.50 3'b111 : x 1.75 Note : By setting this field to 3'b000, the threshold value of the tap can be directly controlled by the threshold adjust field in this register.
  [4:0] RX_REE_TAP2TON_CLIP_4_0 rw — Threshold adjust: Controls how much the threshold can be adjusted by, after multiplying the VGA target gain adjust multiplier with the VGA target gain adjust. Note: This field is a positive number (not twos complement). Note : This field must not be set to a value of 0. Note : The combination of the multiplier and threshold fields in this register controls the positive and negative thresholds for the taps, according to the following equation. Note: The logic associated with this limits the range of the magnitude to 0 to 31, before creating the positive and negative thresholds. +/- ((VGA target gain adjust * VGA target gain adjust multiplier) + Threshold adjust)
0x2E8 WIZ16B8M4CT3_RX_REE_DIAG_CTRL__RX_REE_FIFO_DIAG access per field reset 0x724000
  [23] RX_REE_DIAG_CTRL_7 rw — Analog tap disable: When this bit is set to 1'b1, the rxda_dfe_tap_1_coef, rxda_dfe_tap_2_coef, andrxda_dfe_tap_3_coef signals being driven to the analog will be forced to all 0s.
  [22] RX_REE_DIAG_CTRL_6 rw — Hold periodic equalization while RX idle: When this bit is set to 1'b1, a detection of electrical idle on the receiver (rx_signal_detect is set to 1'b0), will disable the periodic REE general control state machine, and as a result freeze the current state of the parts of the REE that are controlled by it. When a high speed signal is later detected, the REE general control state machine will be enabled again.
  [21] RX_REE_DIAG_CTRL_5 rw — Hold general control state machine 2 equalization while RX idle: When this bit is set to 1'b1, a detection of electrical idle on the receiver (rx_signal_detect is set to 1'b0), will disable the REE general control state machine 2, and as a result freeze the current state of the parts of the REE that are controlled by it. When a high speed signal is later detected, the REE general control state machine will be enabled again.
  [20] RX_REE_DIAG_CTRL_4 rw — Hold general control state machine 1 equalization while RX idle: When this bit is set to 1'b1, a detection of electrical idle on the receiver (rx_signal_detect is set to 1'b0), will disable the REE general control state machine 1, and as a result freeze the current state of the parts of the REE that are controlled by it. When a high speed signal is later detected, the REE general control state machine will be enabled again.
  [17] RX_REE_DIAG_CTRL_1 rw — Enable REE control clock on : Enables the REE control clock. 1'b0: Disabled 1'b1: Enabled
  [16] RX_REE_DIAG_CTRL_0 rw — Force REE function clock on : When active, the REE function clock gate will allow the clock to run. Note: Because of how the REE reset functions are implemented, the REE controller clock must be enabled in order for REE function clock to be enabled. Therefore, if all of the REE control state machines are disabled, the Force REE controller lock on bit in this register must also be set, for this bit to take effect.
  [15] RX_REE_FIFO_DIAG_15 ro — FIFO underflow : Indicates when a FIFO underflow condition has occurred.
  [14] RX_REE_FIFO_DIAG_14 ro — FIFO empty :Indicates that the FIFO is empty.
  [13] RX_REE_FIFO_DIAG_13 rw — FIFO output dequeue : Writing a 1'b1 to this bit will dequeue the current values from the output of the FIFO. Once this register bit is written to a 1'b1, it must be written to a 1'b0 before it is used again to dequeue data.
  [12] RX_REE_FIFO_DIAG_12 rw — FIFO output override enable : Enables the FIFO output override functions. This bit must be set to 1'b1 before enabling the transmitter REE functions. When set, FIFO output dequeues can be performed from this register. When set, the TX equalization evaluator will not be able to dequeue data from the FIFO.
  [11] RX_REE_FIFO_DIAG_11 ro — FIFO output data pre cursor increment : Current value on the pre cursor increment bit on the FIFO output.
  [10] RX_REE_FIFO_DIAG_10 ro — FIFO output data pre cursor decrement : Current value on the pre cursor decrement bit on the FIFO output.
  [9] RX_REE_FIFO_DIAG_9 ro — FIFO output data post cursor increment : Current value on the post cursor increment bit on the FIFO output.
  [8] RX_REE_FIFO_DIAG_8 ro — FIFO output data post cursor decrement : Current value on the post cursor decrement bit on the FIFO output.
  [7] RX_REE_FIFO_DIAG_7 ro — FIFO overflow :Indicates when a FIFO overflow condition has occurred.
  [6] RX_REE_FIFO_DIAG_6 ro — FIFO full :Indicates that the FIFO is full.
  [5] RX_REE_FIFO_DIAG_5 rw — FIFO input enqueue : Writing a 1'b1 to this bit will enqueue the values of the FIFO input data bits in this register to their respective FIFO bits. Once this register bit is written to a 1'b1, it must be written to a 1'b0 before it is used again to dequeue data.
  [4] RX_REE_FIFO_DIAG_4 rw — FIFO input override enable : Enables the FIFO input override functions. This bit must be set to 1'b1 before enabling the transmitter REE functions. When set, FIFO input enqueues can be performed from this register. When set, the TX pre cursor control and TX post cursor control will not be able to enqueue data to the FIFO.
  [3] RX_REE_FIFO_DIAG_3 rw — FIFO input data pre cursor increment : Pre cursor increment value that will be enqueued to the FIFO by the FIFO input enqueue bit in this register.
  [2] RX_REE_FIFO_DIAG_2 rw — FIFO input data pre cursor decrement : Pre cursor decrement value that will be enqueued to the FIFO by the FIFO input enqueue bit in this register.
  [1] RX_REE_FIFO_DIAG_1 rw — FIFO input data post cursor increment : Post cursor increment value that will be enqueued to the FIFO by the FIFO input enqueue bit in this register.
  [0] RX_REE_FIFO_DIAG_0 rw — FIFO input data post cursor decrement : Post cursor decrement value that will be enqueued to the FIFO by the FIFO input enqueue bit in this register.
